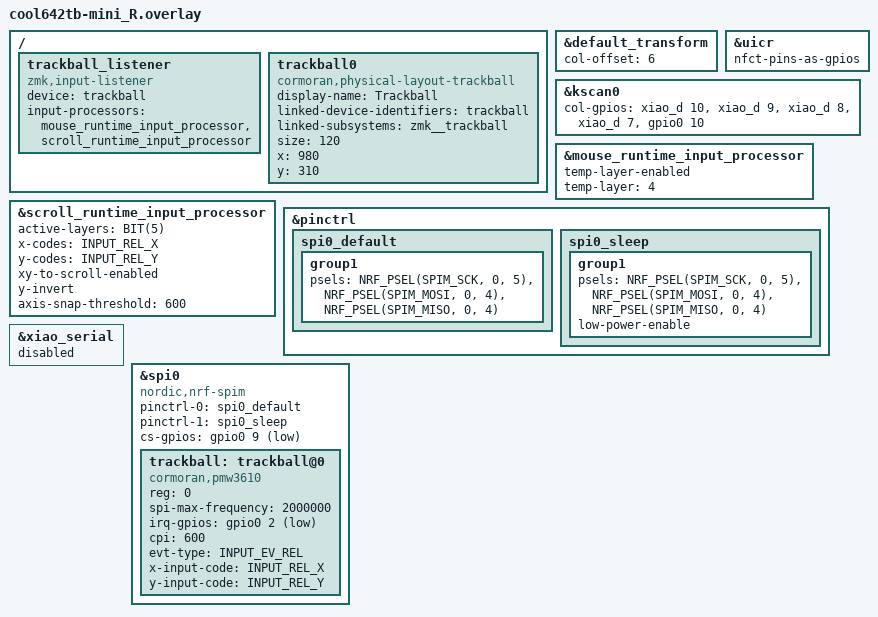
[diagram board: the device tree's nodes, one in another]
#include "cool642tb-mini.dtsi"
#include <zephyr/dt-bindings/input/input-event-codes.h>
#include <input/processors.dtsi>
#include <input/processors/runtime-input-processor.dtsi>
#include <dt-bindings/zmk/runtime_input_processor.h>

&default_transform {
    col-offset = <6>;
};

&uicr {
    nfct-pins-as-gpios;
};

&kscan0 {
        col-gpios
            = <&xiao_d 10 GPIO_ACTIVE_HIGH>
            , <&xiao_d 9 GPIO_ACTIVE_HIGH> 
            , <&xiao_d 8 GPIO_ACTIVE_HIGH> 
            , <&xiao_d 7 GPIO_ACTIVE_HIGH> 
            , <&gpio0 10 GPIO_ACTIVE_HIGH>
            ;
};

/ {
    // ==============================================================================
    // Input Listener: トラックボール（マウス操作）
    // ==============================================================================
    trackball_listener {
        compatible = "zmk,input-listener";
        device = <&trackball>;
        input-processors = <&mouse_runtime_input_processor &scroll_runtime_input_processor>;
    };

    // ==============================================================================
    // 物理レイアウト: トラックボール (DYA Studio で表示)
    // ==============================================================================
    trackball0: trackball0 {
        compatible = "cormoran,physical-layout-trackball";
        display-name = "Trackball";
        linked-device-identifiers = "trackball";     // デバイス識別子（文字列）
        linked-subsystems = "zmk__trackball";        // ZMK サブシステム（必須）
        size = <120>;        // トラックボールの表示サイズ (120 = 1.2u 相当)
        x = <980>;          // X 座標 (右側、キーの右下あたり)
        y = <310>;           // Y 座標 (下側)
    };
};

&mouse_runtime_input_processor {
	temp-layer-enabled;
	temp-layer = <4>;
};

&scroll_runtime_input_processor {
	active-layers = <BIT(5)>;
	
	x-codes = <INPUT_REL_X>;
	y-codes = <INPUT_REL_Y>;
	xy-to-scroll-enabled;
    y-invert;
	
	// axis-snap-mode = <AXIS_SNAP_MODE_Y>;
	axis-snap-threshold = <600>;
};

&pinctrl {
    spi0_default: spi0_default {
        group1 {
            psels = <NRF_PSEL(SPIM_SCK, 0, 5)>,
                <NRF_PSEL(SPIM_MOSI, 0, 4)>,
                <NRF_PSEL(SPIM_MISO, 0, 4)>;
        };
    };

    spi0_sleep: spi0_sleep {
        group1 {
            psels = <NRF_PSEL(SPIM_SCK, 0, 5)>,
                <NRF_PSEL(SPIM_MOSI, 0, 4)>,
                <NRF_PSEL(SPIM_MISO, 0, 4)>;
            low-power-enable;
        };
    };
};

&xiao_serial { status = "disabled"; };

&spi0 {
    status = "okay";
    compatible = "nordic,nrf-spim";
    pinctrl-0 = <&spi0_default>;
    pinctrl-1 = <&spi0_sleep>;
    pinctrl-names = "default", "sleep";
    cs-gpios = <&gpio0 9 GPIO_ACTIVE_LOW>;

    trackball: trackball@0 {
        status = "okay";
        compatible = "cormoran,pmw3610";
        reg = <0>;
        spi-max-frequency = <2000000>;
        irq-gpios = <&gpio0 2 (GPIO_ACTIVE_LOW | GPIO_PULL_UP)>;
        cpi = <600>;  // CPI 設定（200-3200、ステップ 200）
        evt-type = <INPUT_EV_REL>;
        x-input-code = <INPUT_REL_X>;
        y-input-code = <INPUT_REL_Y>;
    };
};
